# STM32G431VBT7 register map
File version: 1.0
Registers are 32-bit, access not given, reset 0x0 unless marked. A register's access mark holds for its fields unless they carry their own. Offsets are from the block's base; [hi:lo] are bit positions; {n}, {i} and the like mark numbered series.

## LPTIM1
Base 0x40007C00
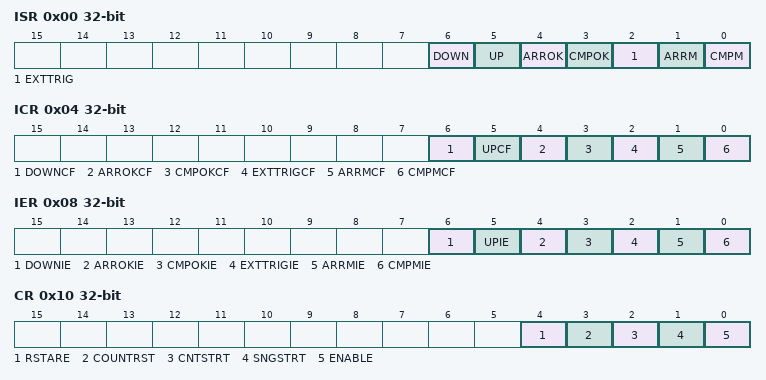
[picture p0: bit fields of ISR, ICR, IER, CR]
0x00 ISR
  [6] DOWN, [5] UP, [4] ARROK, [3] CMPOK, [2] EXTTRIG, [1] ARRM, [0] CMPM
0x04 ICR
  [6] DOWNCF, [5] UPCF, [4] ARROKCF, [3] CMPOKCF, [2] EXTTRIGCF, [1] ARRMCF, [0] CMPMCF
0x08 IER
  [6] DOWNIE, [5] UPIE, [4] ARROKIE, [3] CMPOKIE, [2] EXTTRIGIE, [1] ARRMIE, [0] CMPMIE
0x0C CFGR
  [24] ENC, [23] COUNTMODE, [22] PRELOAD, [21] WAVPOL, [20] WAVE, [19] TIMOUT, [18:17] TRIGEN, [29:13] TRIGSEL, [11:9] PRESC, [7:6] TRGFLT, [4:3] CKFLT, [2:1] CKPOL, [0] CKSEL
0x10 CR
  [4] RSTARE, [3] COUNTRST, [2] CNTSTRT, [1] SNGSTRT, [0] ENABLE
0x14 CMP
  [15:0] CMP
0x18 ARR
  [15:0] ARR
0x1C CNT
  [15:0] CNT
0x20 OR
  [5:1] IN2, [3:0] IN1

## UCPD1
Base 0x4000A000
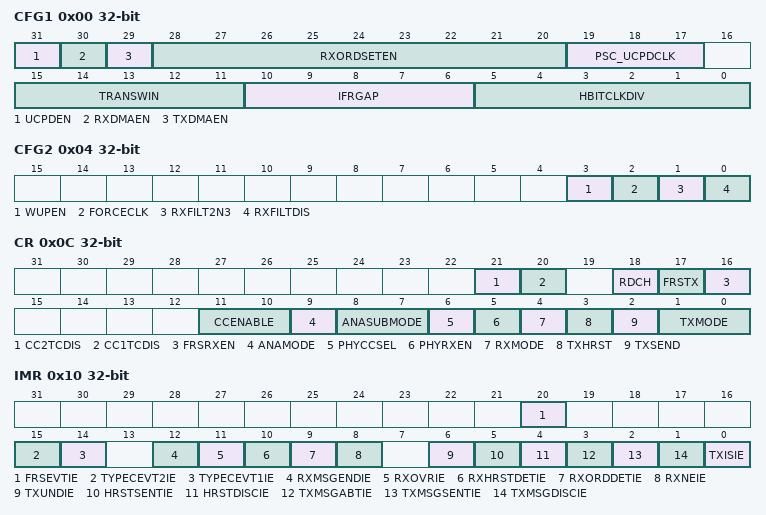
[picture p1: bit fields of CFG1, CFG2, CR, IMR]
0x00 CFG1
  [31] UCPDEN, [30] RXDMAEN, [29] TXDMAEN, [28:20] RXORDSETEN, [19:17] PSC_UCPDCLK, [15:11] TRANSWIN, [10:6] IFRGAP, [5:0] HBITCLKDIV
0x04 CFG2
  [3] WUPEN, [2] FORCECLK, [1] RXFILT2N3, [0] RXFILTDIS
0x0C CR
  [21] CC2TCDIS, [20] CC1TCDIS, [18] RDCH, [17] FRSTX, [16] FRSRXEN, [11:10] CCENABLE, [9] ANAMODE, [8:7] ANASUBMODE, [6] PHYCCSEL, [5] PHYRXEN, [4] RXMODE, [3] TXHRST, [2] TXSEND, [1:0] TXMODE
0x10 IMR
  [20] FRSEVTIE, [15] TYPECEVT2IE, [14] TYPECEVT1IE, [12] RXMSGENDIE, [11] RXOVRIE, [10] RXHRSTDETIE, [9] RXORDDETIE, [8] RXNEIE, [6] TXUNDIE, [5] HRSTSENTIE, [4] HRSTDISCIE, [3] TXMSGABTIE, [2] TXMSGSENTIE, [1] TXMSGDISCIE, [0] TXISIE
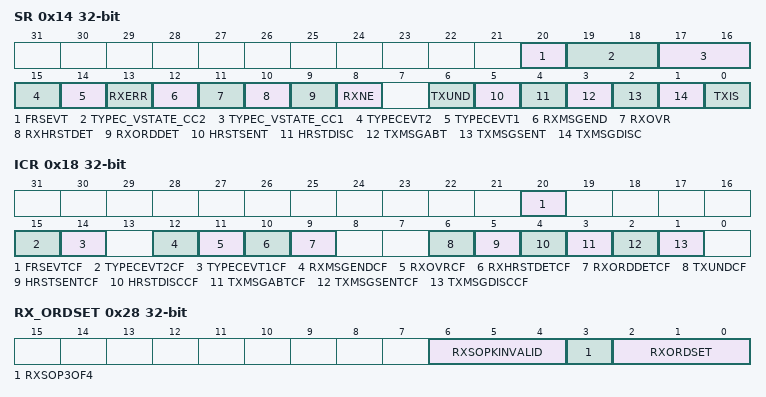
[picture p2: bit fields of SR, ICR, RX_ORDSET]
0x14 SR
  [20] FRSEVT, [19:18] TYPEC_VSTATE_CC2, [17:16] TYPEC_VSTATE_CC1, [15] TYPECEVT2, [14] TYPECEVT1, [13] RXERR, [12] RXMSGEND, [11] RXOVR, [10] RXHRSTDET, [9] RXORDDET, [8] RXNE, [6] TXUND, [5] HRSTSENT, [4] HRSTDISC, [3] TXMSGABT, [2] TXMSGSENT, [1] TXMSGDISC, [0] TXIS
0x18 ICR
  [20] FRSEVTCF, [15] TYPECEVT2CF, [14] TYPECEVT1CF, [12] RXMSGENDCF, [11] RXOVRCF, [10] RXHRSTDETCF, [9] RXORDDETCF, [6] TXUNDCF, [5] HRSTSENTCF, [4] HRSTDISCCF, [3] TXMSGABTCF, [2] TXMSGSENTCF, [1] TXMSGDISCCF
0x1C TX_ORDSET
  [19:0] TXORDSET
0x20 TX_PAYSZ
  [9:0] TXPAYSZ
0x24 TXDR
  [7:0] TXDATA
0x28 RX_ORDSET
  [6:4] RXSOPKINVALID, [3] RXSOP3OF4, [2:0] RXORDSET
0x2C RX_PAYSZ
  [9:0] RXPAYSZ
0x30 RXDR
  [7:0] RXDATA
0x34 RX_ORDEXT1
  [19:0] RXSOPX1
0x38 RX_ORDEXT2
  [19:0] RXSOPX2

## SYSCFG
Base 0x40010000
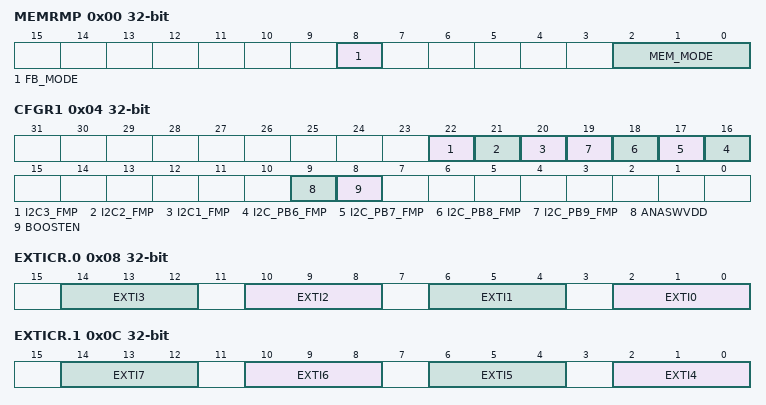
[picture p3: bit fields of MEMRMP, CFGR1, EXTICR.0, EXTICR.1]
0x00 MEMRMP
  [8] FB_MODE, [2:0] MEM_MODE
0x04 CFGR1
  [22] I2C3_FMP, [21] I2C2_FMP, [20] I2C1_FMP, [n+10] I2C_PB{n}_FMP (n=6..9), [9] ANASWVDD, [8] BOOSTEN
0x08 EXTICR.0
  [4n+2:4n] EXTI{n} (n=0..3)
0x0C EXTICR.1
  [4n-14:4n-16] EXTI{n} (n=4..7)
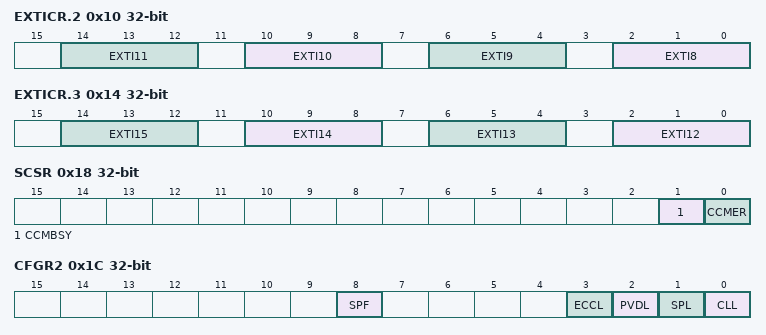
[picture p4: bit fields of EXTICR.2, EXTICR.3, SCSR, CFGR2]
0x10 EXTICR.2
  [4n-30:4n-32] EXTI{n} (n=8..11)
0x14 EXTICR.3
  [4n-46:4n-48] EXTI{n} (n=12..15)
0x18 SCSR
  [1] CCMBSY, [0] CCMER
0x1C CFGR2
  [8] SPF, [3] ECCL, [2] PVDL, [1] SPL, [0] CLL
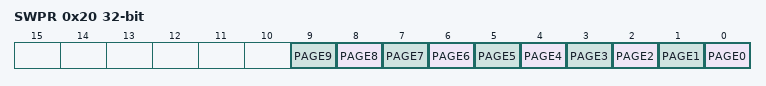
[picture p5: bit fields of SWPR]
0x20 SWPR
  [n] PAGE{n} (n=0..9)
0x24 SKR
  [7:0] KEY

## VREFBUF
Base 0x40010030
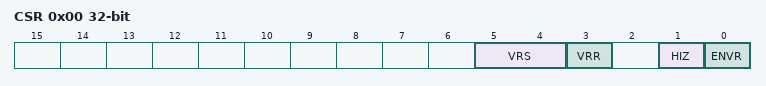
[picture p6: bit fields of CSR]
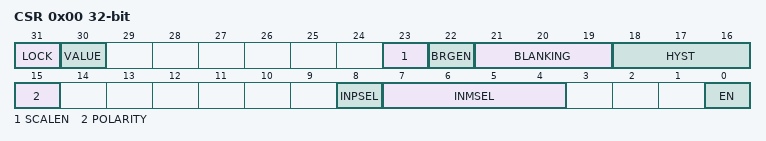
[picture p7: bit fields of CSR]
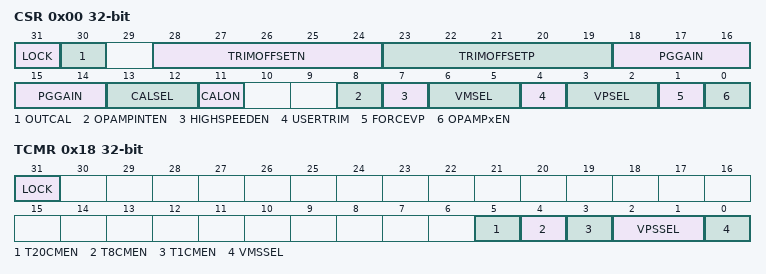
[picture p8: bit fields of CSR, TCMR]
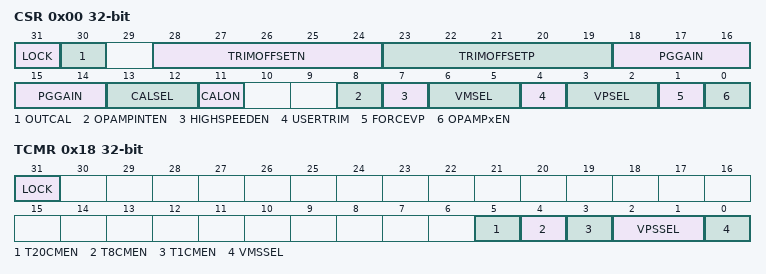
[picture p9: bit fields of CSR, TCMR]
0x00 CSR
  [5:4] VRS, [3] VRR, [1] HIZ, [0] ENVR
0x04 CCR
  [5:0] TRIM

## COMP1
Base 0x40010200
Same registers: COMP2 0x40010204, COMP3 0x40010208, COMP4 0x4001020C
0x00 CSR
  [31] LOCK, [30] VALUE, [23] SCALEN, [22] BRGEN, [21:19] BLANKING, [18:16] HYST, [15] POLARITY, [8] INPSEL, [7:4] INMSEL, [0] EN

## OPAMP
Base 0x40010300
0x00 CSR
  [31] LOCK, [30] OUTCAL, [28:24] TRIMOFFSETN, [23:19] TRIMOFFSETP, [18:14] PGGAIN, [13:12] CALSEL, [11] CALON, [8] OPAMPINTEN, [7] HIGHSPEEDEN, [6:5] VMSEL, [4] USERTRIM, [3:2] VPSEL, [1] FORCEVP, [0] OPAMPxEN
0x18 TCMR
  [31] LOCK, [5] T20CMEN, [4] T8CMEN, [3] T1CMEN, [2:1] VPSSEL, [0] VMSSEL

## OPAMP1
Base 0x40010300
Same registers: OPAMP2 0x40010304, OPAMP3 0x40010308
0x00 CSR
  [31] LOCK, [30] OUTCAL, [28:24] TRIMOFFSETN, [23:19] TRIMOFFSETP, [18:14] PGGAIN, [13:12] CALSEL, [11] CALON, [8] OPAMPINTEN, [7] HIGHSPEEDEN, [6:5] VMSEL, [4] USERTRIM, [3:2] VPSEL, [1] FORCEVP, [0] OPAMPxEN
0x18 TCMR
  [31] LOCK, [5] T20CMEN, [4] T8CMEN, [3] T1CMEN, [2:1] VPSSEL, [0] VMSSEL
